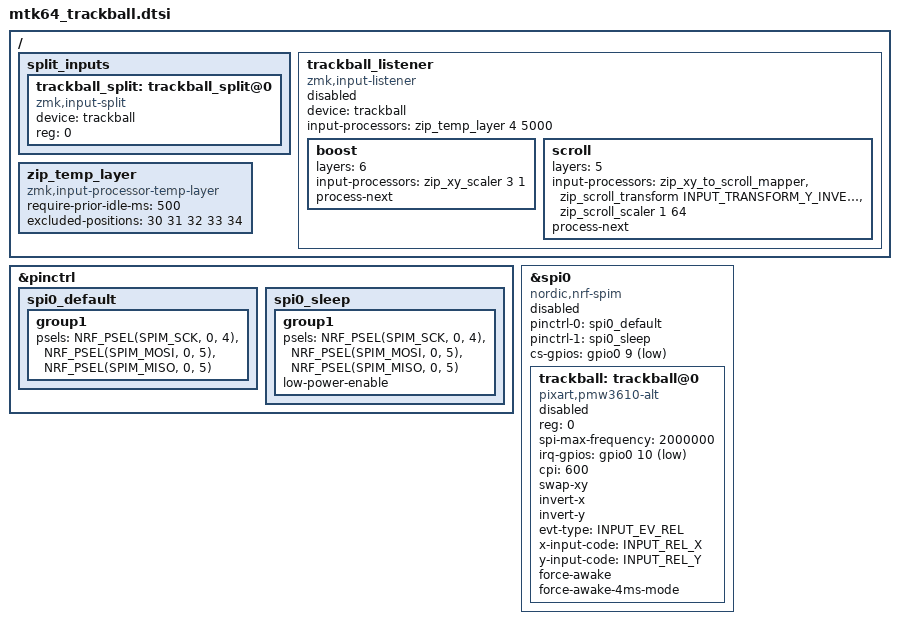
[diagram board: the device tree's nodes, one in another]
#include <zephyr/dt-bindings/input/input-event-codes.h>
#include <dt-bindings/zmk/input_transform.h>
#include <input/processors.dtsi>

&pinctrl {
    spi0_default: spi0_default {
        group1 {
            psels = <NRF_PSEL(SPIM_SCK, 0, 4)>,
                <NRF_PSEL(SPIM_MOSI, 0, 5)>,
                <NRF_PSEL(SPIM_MISO, 0, 5)>;
        };
    };

    spi0_sleep: spi0_sleep {
        group1 {
            psels = <NRF_PSEL(SPIM_SCK, 0, 4)>,
                <NRF_PSEL(SPIM_MOSI, 0, 5)>,
                <NRF_PSEL(SPIM_MISO, 0, 5)>;
            low-power-enable;
        };
    };
};

&spi0 {
    status = "disabled";
    compatible = "nordic,nrf-spim";
    pinctrl-0 = <&spi0_default>;
    pinctrl-1 = <&spi0_sleep>;
    pinctrl-names = "default", "sleep";
    cs-gpios = <&gpio0 9 GPIO_ACTIVE_LOW>;

    trackball: trackball@0 {
        status = "disabled";
        compatible = "pixart,pmw3610-alt";
        reg = <0>;
        spi-max-frequency = <2000000>;
        irq-gpios = <&gpio0 10 (GPIO_ACTIVE_LOW | GPIO_PULL_UP)>;
        // 1000 → 600 (2026-08-17)。本人の申告は次の2つ。
        //   ・ターゲット近くで指先を遅くして微調整するとき、指の震えがそのままカーソルに出る
        //   ・指をボールから離した瞬間にカーソルが少し動いてターゲットを外す
        // どちらも「指の動きの物理的な幅」は変わらないので、cpi を下げれば比例して小さくなる。
        // 画面を横切る速さは macOS 側の加速 (軌跡の速さ=3・加速あり) がある程度 面倒を見る。
        // 横切るのが遅すぎると感じたら、cpi を戻すのではなく「押している間だけ高速」の
        // レイヤーを足す。ただし置き場所は左手に限る —— 右手の親指はボールを転がしているので
        // 位置54/55/61/65 は使えない (2026-08-17 に判明)。
        cpi = <600>;
        swap-xy;
        invert-x;
        invert-y;
        evt-type = <INPUT_EV_REL>;
        x-input-code = <INPUT_REL_X>;
        y-input-code = <INPUT_REL_Y>;

        force-awake;
        /* keep the sensor awake while ZMK activity state is ACTIVE,
           fallback to normal downshift mode after ZMK goes into IDLE / SLEEP mode.
           thus, the sensor would be a `wakeup-source` */

        force-awake-4ms-mode;
        /* while force-awake is acitvated, enable this mode to force sampling per 
           4ms, where the default sampling rate is 8ms. */
        /* NOTE: apply this mode if you need 250Hz with direct USB connection. */

    };
};

/ {
    split_inputs {
        #address-cells = <1>;
        #size-cells = <0>;

        trackball_split: trackball_split@0 {
            device = <&trackball>;
            compatible = "zmk,input-split";
            reg = <0>;
        };
    };

    trackball_listener: trackball_listener {
        compatible = "zmk,input-listener";
        status = "disabled";
        device = <&trackball>;

        // レイヤー番号は config/mtk64.keymap の LY_* と必ずそろえること。
        // 2026-08-16 の工程2 で8枚構成にしたとき snipe 1→6 / scroll 3→5 /
        // zip_temp_layer 6→4 につけ替えた。片方だけ直すと全部 別のレイヤーを見にいく。
        // レイヤー6 は SNIPE (遅くする) から BOOST (速くする) に作り替えた (2026-08-17)。
        // cpi=600 で微調整はやりやすくなったが、画面を横切るのが大変になったため。
        //   ・遅くするキーは要らなくなった。既定そのものが遅いので
        //   ・速くするキーは 位置58（外側のノブの押し込み）に置いた。左手の親指で押す。
        //     右手の親指はボールを転がしているので、右親指のキーには置けない
        // 3倍で 600×3 = 1800 相当。元の既定 1000 より速いので、横切るのは前より楽になるはず。
        // 速すぎたら 2、足りなければ 4 にする。
        boost {
        layers = <6>;
        input-processors = <&zip_xy_scaler 3 1>;
        process-next;
        };

        scroll {
        layers = <5>;
        // 1. X/Y をホイールに読み替える
        // 2. 縦だけ反転する (2026-08-13。カーソルの向きは変えない。
        //    zip_scroll_transform は WHEEL/HWHEEL に効くので必ず mapper の後ろに置く)
        // 3. 倍率。1 4 も試したが速すぎたので 1 64 に戻した (2026-08-13)。工程3 で詰める。
        input-processors = <&zip_xy_to_scroll_mapper>,
                           <&zip_scroll_transform INPUT_TRANSFORM_Y_INVERT>,
                           <&zip_scroll_scaler 1 64>;
        process-next;
        };

        input-processors = <&zip_temp_layer 4 5000>;

    };

    zip_temp_layer: zip_temp_layer {
        compatible = "zmk,input-processor-temp-layer";
        #input-processor-cells = <2>;
        require-prior-idle-ms = <500>;
        // ここに書いた位置はマウスレイヤーを解除しない。クリックを置いた位置と必ず一致させる。
        // 2026-08-13 に 43-47 (] N M , .) から右手ホームロー 30-34 (H J K L ;) へ移した。
        // 2026-08-16 に本人が実機で確認: ボールを転がしたまま J を押し続けて範囲選択ができる。
        // 同じ手でも成立するので、SPEC が書いていた「左手へ移す」案は採らず右手に据え置く。
        excluded-positions = <
            30  // H  戻る (MB4)
            31  // J  左クリック (MB1)
            32  // K  右クリック (MB2)
            33  // L  中クリック (MB3)
            34  // ;  進む (MB5)
        >;
    };

};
